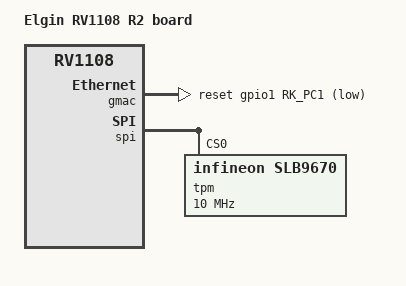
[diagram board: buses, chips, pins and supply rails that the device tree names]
// SPDX-License-Identifier: (GPL-2.0+ OR MIT)

/*
 * Copyright (C) 2018 O.S. Systems Software LTDA.
 */

/dts-v1/;

#include "rv1108-elgin.dtsi"

/ {
	model = "Elgin RV1108 R2 board";
	compatible = "elgin,rv1108-r2", "rockchip,rv1108";

};

&gmac {
	clock_in_out = "output";
	pinctrl-names = "default";
	pinctrl-0 = <&rmii_pins>;
	snps,reset-gpio = <&gpio1 RK_PC1 GPIO_ACTIVE_LOW>;
	snps,reset-active-low;
	snps,reset-delays-us = <0 20000 20000>;
	status = "okay";
};

&spi {
	pinctrl-names = "default";
	pinctrl-0 = <&spim1_clk &spim1_cs0 &spim1_tx &spim1_rx>;
	/delete-property/ dmas;
	/delete-property/ dma-names;
	status = "okay";

	tpm@0 {
		compatible = "infineon,slb9670", "tcg,tpm_tis-spi";
		reg = <0>;
		spi-max-frequency = <10000000>;
	};
};
